# STM32L4R9xx register map
File version: 1.0
Registers are 32-bit, access not given, reset 0x0 unless marked. A register's access mark holds for its fields unless they carry their own. Offsets are from the block's base; [hi:lo] are bit positions; {n}, {i} and the like mark numbered series; 'fields as' and 'values as' point back to an identical list.

## OPAMP12_COMMON
Base 0x40007800
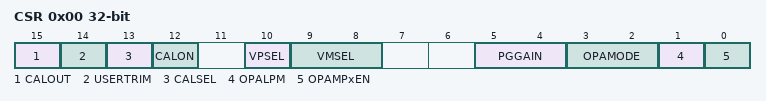
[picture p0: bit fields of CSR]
0x00 CSR
  [15] CALOUT, [14] USERTRIM, [13] CALSEL, [12] CALON, [10] VPSEL, [9:8] VMSEL, [5:4] PGGAIN, [3:2] OPAMODE, [1] OPALPM, [0] OPAMPxEN

## LPTIM1
Base 0x40007C00
Same registers: LPTIM2 0x40009400
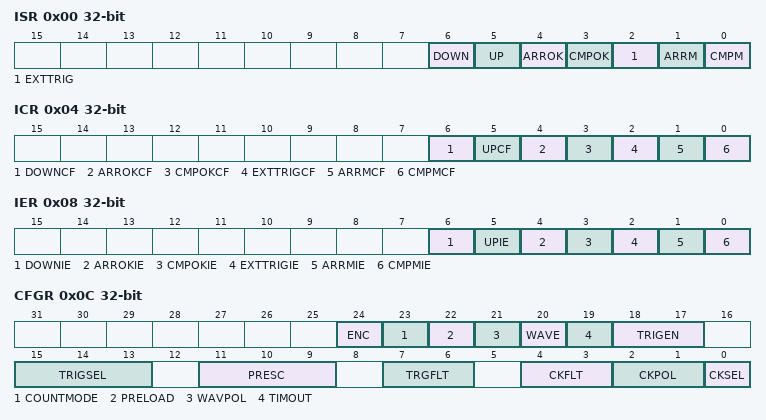
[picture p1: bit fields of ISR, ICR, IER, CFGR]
0x00 ISR
  [6] DOWN, [5] UP, [4] ARROK, [3] CMPOK, [2] EXTTRIG, [1] ARRM, [0] CMPM
0x04 ICR
  [6] DOWNCF, [5] UPCF, [4] ARROKCF, [3] CMPOKCF, [2] EXTTRIGCF, [1] ARRMCF, [0] CMPMCF
0x08 IER
  [6] DOWNIE, [5] UPIE, [4] ARROKIE, [3] CMPOKIE, [2] EXTTRIGIE, [1] ARRMIE, [0] CMPMIE
0x0C CFGR
  [24] ENC, [23] COUNTMODE, [22] PRELOAD, [21] WAVPOL, [20] WAVE, [19] TIMOUT, [18:17] TRIGEN, [15:13] TRIGSEL, [11:9] PRESC, [7:6] TRGFLT, [4:3] CKFLT, [2:1] CKPOL, [0] CKSEL
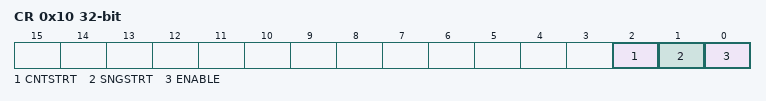
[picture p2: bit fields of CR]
0x10 CR
  [2] CNTSTRT, [1] SNGSTRT, [0] ENABLE
0x14 CMP
  [15:0] CMP
0x18 ARR
  [15:0] ARR
0x1C CNT
  [15:0] CNT
0x20 OR
  [1:0] OR

## SYSCFG
Base 0x40010000
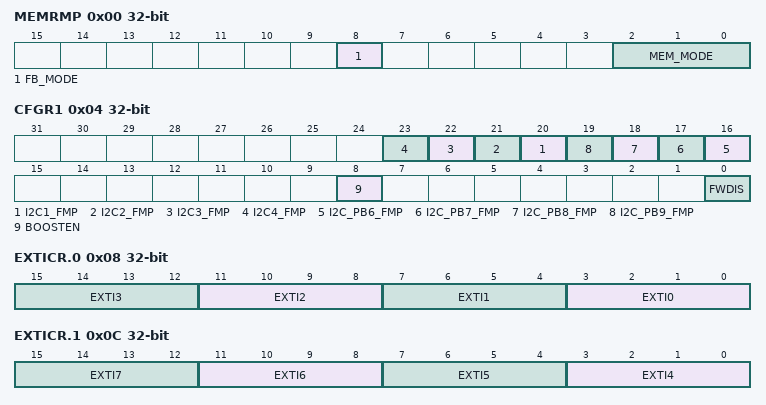
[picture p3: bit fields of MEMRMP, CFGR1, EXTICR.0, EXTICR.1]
0x00 MEMRMP
  [8] FB_MODE, [2:0] MEM_MODE
0x04 CFGR1
  [n+19] I2C{n}_FMP (n=1..4), [n+10] I2C_PB{n}_FMP (n=6..9), [8] BOOSTEN, [0] FWDIS
0x08 EXTICR.0
  [4n+3:4n] EXTI{n} (n=0..3)
0x0C EXTICR.1
  [4n-13:4n-16] EXTI{n} (n=4..7)
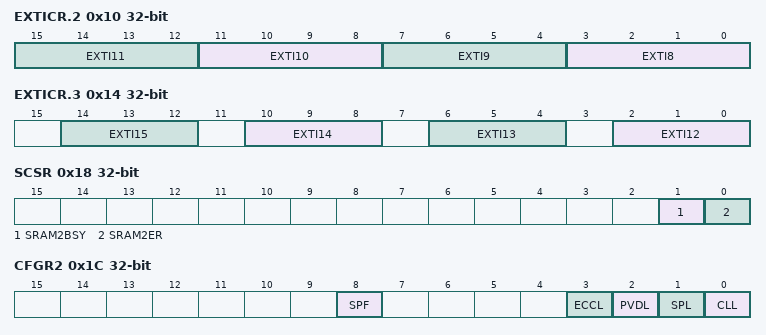
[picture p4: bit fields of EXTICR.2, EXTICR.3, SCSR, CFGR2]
0x10 EXTICR.2
  [4n-29:4n-32] EXTI{n} (n=8..11)
0x14 EXTICR.3
  [4n-46:4n-48] EXTI{n} (n=12..15)
0x18 SCSR
  [1] SRAM2BSY, [0] SRAM2ER
0x1C CFGR2
  [8] SPF, [3] ECCL, [2] PVDL, [1] SPL, [0] CLL
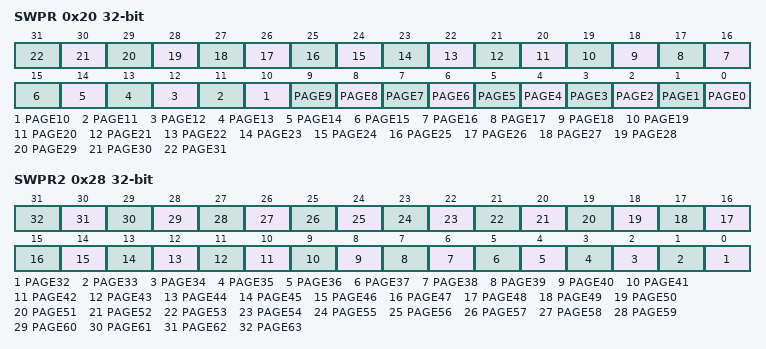
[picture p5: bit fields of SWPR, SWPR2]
0x20 SWPR
  [n] PAGE{n} (n=0..31)
0x24 SKR
  [7:0] KEY
0x28 SWPR2
  [n-32] PAGE{n} (n=32..63)

## VREFBUF
Base 0x40010030
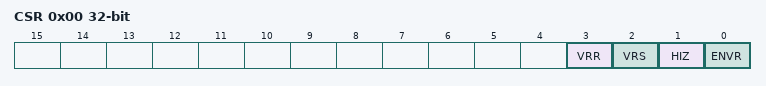
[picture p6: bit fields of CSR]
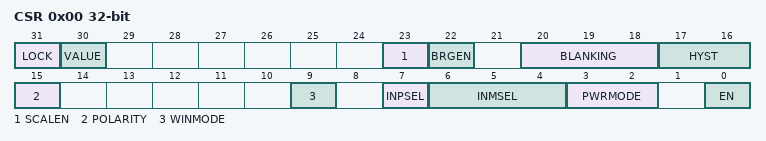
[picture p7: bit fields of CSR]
0x00 CSR
  [3] VRR, [2] VRS, [1] HIZ, [0] ENVR
0x04 CCR
  [5:0] TRIM

## COMP1
Base 0x40010200
Same registers: COMP2 0x40010204, COMP12_COMMON 0x40010204
0x00 CSR
  [31] LOCK, [30] VALUE, [23] SCALEN, [22] BRGEN, [20:18] BLANKING, [17:16] HYST, [15] POLARITY, [9] WINMODE, [7] INPSEL, [6:4] INMSEL, [3:2] PWRMODE, [0] EN

## EXTI
Base 0x40010400
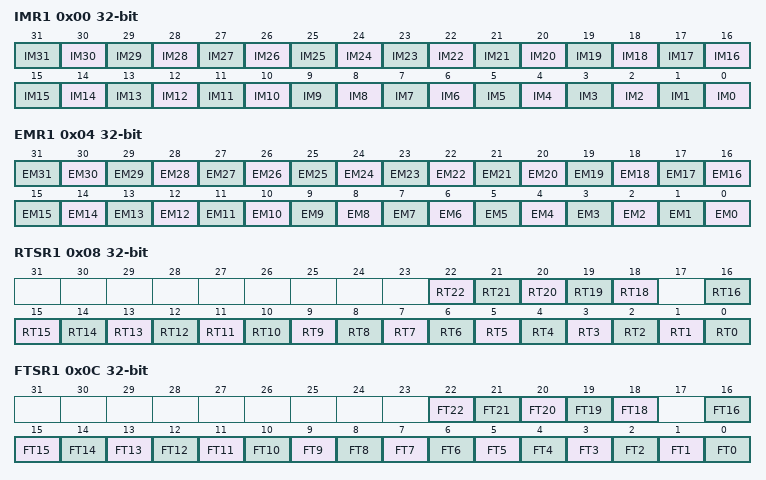
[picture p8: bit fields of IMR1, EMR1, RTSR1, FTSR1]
0x00 IMR1
  [n] IM{n} (n=0..31)
0x04 EMR1
  [n] EM{n} (n=0..31)
0x08 RTSR1
  [n] RT{n} (n=18..22), [n] RT{n} (n=0..16)
0x0C FTSR1
  [n] FT{n} (n=18..22), [n] FT{n} (n=0..16)
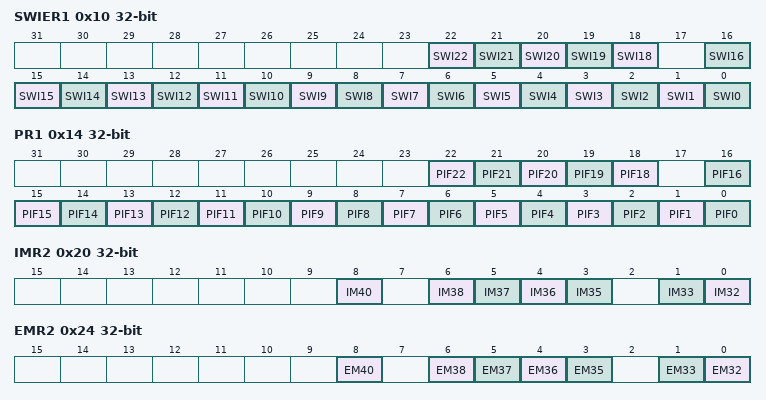
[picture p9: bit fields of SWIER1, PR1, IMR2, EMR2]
0x10 SWIER1
  [n] SWI{n} (n=18..22), [n] SWI{n} (n=0..16)
0x14 PR1
  [n] PIF{n} (n=18..22), [n] PIF{n} (n=0..16)
0x20 IMR2
  [8] IM40, [n-32] IM{n} (n=35..38), [1] IM33, [0] IM32
0x24 EMR2
  [8] EM40, [n-32] EM{n} (n=35..38), [1] EM33, [0] EM32
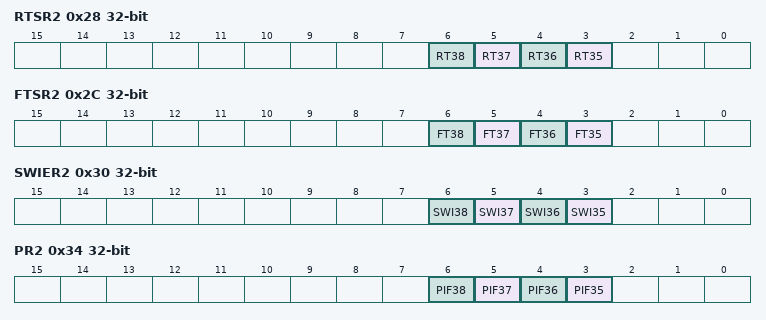
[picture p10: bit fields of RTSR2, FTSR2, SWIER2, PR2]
0x28 RTSR2
  [n-32] RT{n} (n=35..38)
0x2C FTSR2
  [n-32] FT{n} (n=35..38)
0x30 SWIER2
  [n-32] SWI{n} (n=35..38)
0x34 PR2
  [n-32] PIF{n} (n=35..38)

## FIREWALL
Base 0x40011C00
0x00 CSSA
0x04 CSL
0x08 NVDSSA
0x0C NVDSL
0x10 VDSSA
0x14 VDSL
0x20 CR

## SAI1
Base 0x40015400
Same registers: SAI2 0x40015800
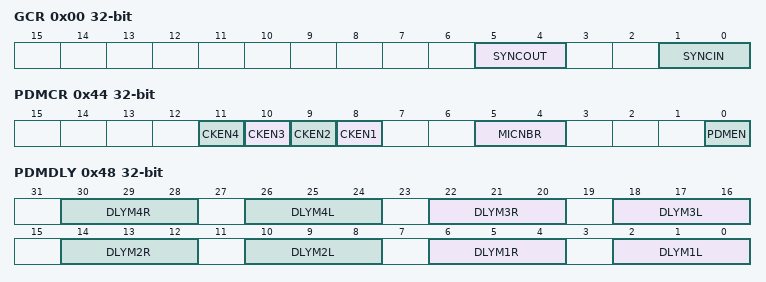
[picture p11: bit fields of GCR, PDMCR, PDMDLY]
0x00 GCR
  [5:4] SYNCOUT, [1:0] SYNCIN
0x04 CR1A
0x08 CR2A
0x10 FRCRA
0x1C SLOTRA
0x24 CR1B
0x28 CR2B
0x2C IMRA
0x30 FRCRB
0x3C SLOTRB
0x40 SRA
0x44 PDMCR
  [n+7] CKEN{n} (n=1..4), [5:4] MICNBR, [0] PDMEN
0x48 PDMDLY
  [8n-2:8n-4] DLYM{n}R (n=1..4), [8n-6:8n-8] DLYM{n}L (n=1..4)
0x4C IMRB
0x58 CLRFRA
0x60 SRB
0x74 DRA
0x78 CLRFRB
0x94 DRB

## DFSDM1
Base 0x40016000
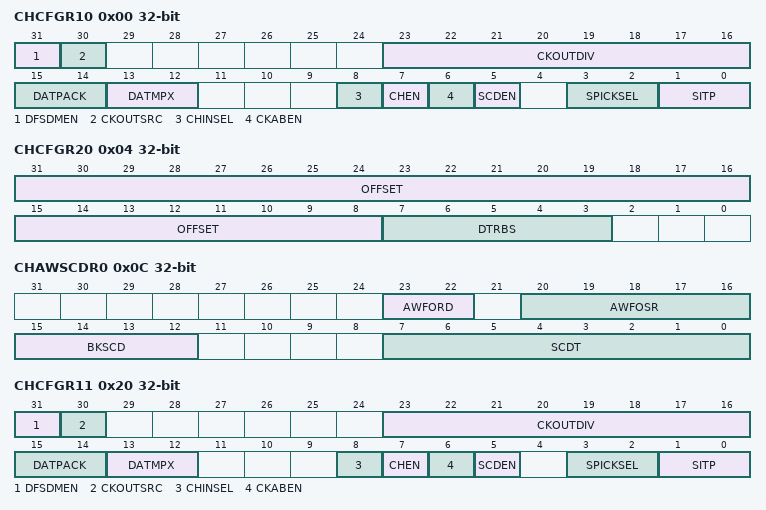
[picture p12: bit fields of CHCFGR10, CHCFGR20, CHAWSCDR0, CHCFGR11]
0x00 CHCFGR10
  [31] DFSDMEN, [30] CKOUTSRC, [23:16] CKOUTDIV, [15:14] DATPACK, [13:12] DATMPX, [8] CHINSEL, [7] CHEN, [6] CKABEN, [5] SCDEN, [3:2] SPICKSEL, [1:0] SITP
0x04 CHCFGR20
  [31:8] OFFSET, [7:3] DTRBS
0x0C CHAWSCDR0
  [23:22] AWFORD, [20:16] AWFOSR, [15:12] BKSCD, [7:0] SCDT
0x18 CHWDATAR0
0x20 CHCFGR11
  fields as CHCFGR10
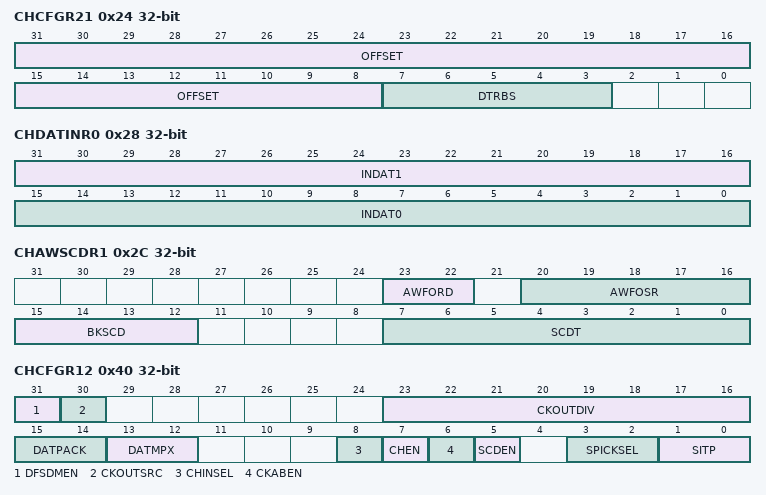
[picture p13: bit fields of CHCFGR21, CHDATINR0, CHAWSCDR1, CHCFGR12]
0x24 CHCFGR21
  [31:8] OFFSET, [7:3] DTRBS
0x28 CHDATINR0
  [31:16] INDAT1, [15:0] INDAT0
0x2C CHAWSCDR1
  [23:22] AWFORD, [20:16] AWFOSR, [15:12] BKSCD, [7:0] SCDT
0x38 CHWDATAR1
0x3C CHDLYR0
  [5:0] PLSSKP
0x40 CHCFGR12
  fields as CHCFGR10
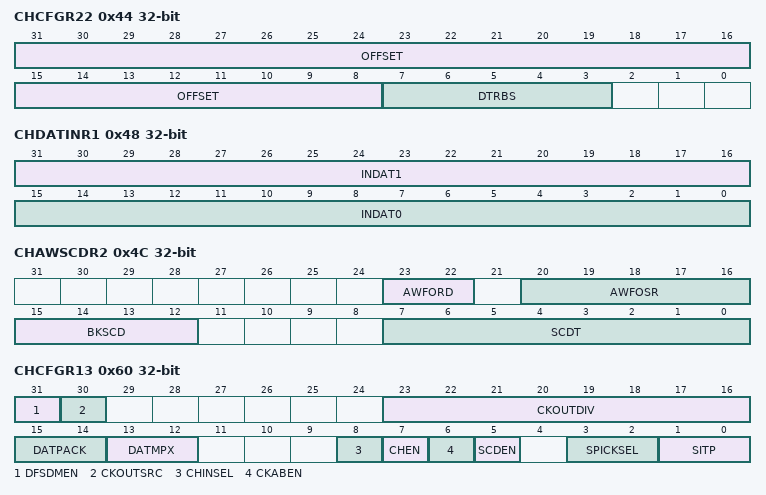
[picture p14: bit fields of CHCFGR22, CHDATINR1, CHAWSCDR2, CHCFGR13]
0x44 CHCFGR22
  [31:8] OFFSET, [7:3] DTRBS
0x48 CHDATINR1
  [31:16] INDAT1, [15:0] INDAT0
0x4C CHAWSCDR2
  [23:22] AWFORD, [20:16] AWFOSR, [15:12] BKSCD, [7:0] SCDT
0x58 CHWDATAR2
0x5C CHDLYR1
  [5:0] PLSSKP
0x60 CHCFGR13
  fields as CHCFGR10
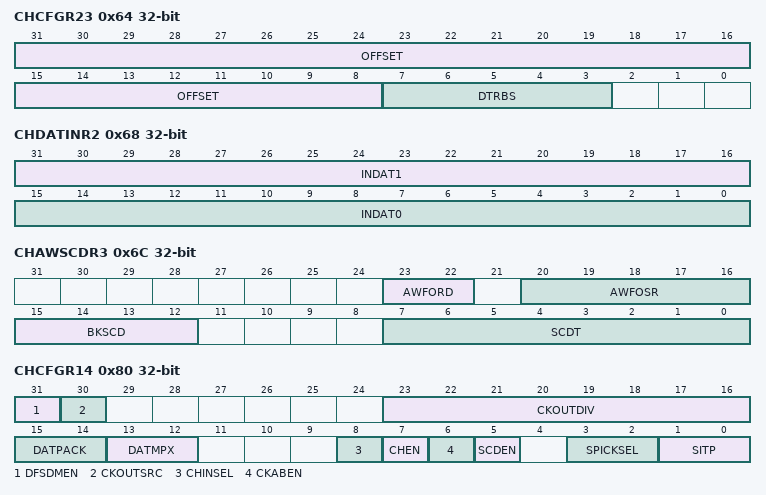
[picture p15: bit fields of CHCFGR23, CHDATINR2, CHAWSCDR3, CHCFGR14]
0x64 CHCFGR23
  [31:8] OFFSET, [7:3] DTRBS
0x68 CHDATINR2
  [31:16] INDAT1, [15:0] INDAT0
0x6C CHAWSCDR3
  [23:22] AWFORD, [20:16] AWFOSR, [15:12] BKSCD, [7:0] SCDT
0x78 CHWDATAR3
0x7C CHDLYR2
  [5:0] PLSSKP
0x80 CHCFGR14
  fields as CHCFGR10
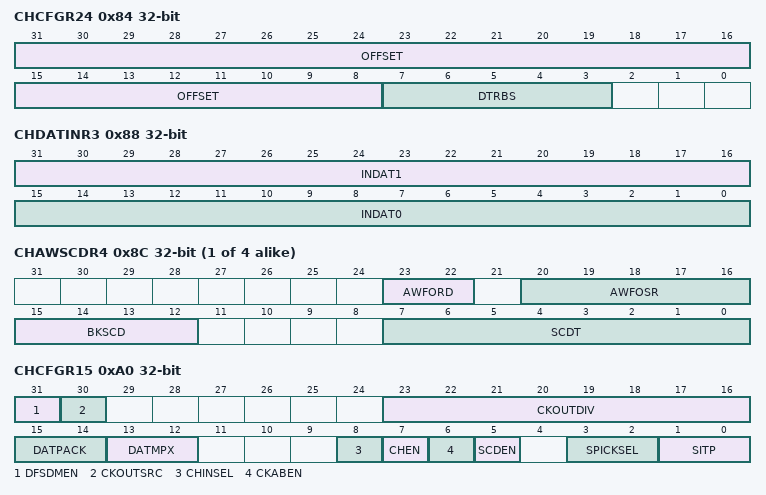
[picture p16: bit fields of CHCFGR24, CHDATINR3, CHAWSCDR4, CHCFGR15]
0x84 CHCFGR24
  [31:8] OFFSET, [7:3] DTRBS
0x88 CHDATINR3
  [31:16] INDAT1, [15:0] INDAT0
{0xC+0x20*i} CHAWSCDR{i} (i=4..7)
  [23:22] AWFORD, [20:16] AWFOSR, [15:12] BKSCD, [7:0] SCDT
{0x18+0x20*i} CHWDATAR{i} (i=4..7)
0x9C CHDLYR3
  [5:0] PLSSKP
0xA0 CHCFGR15
  fields as CHCFGR10
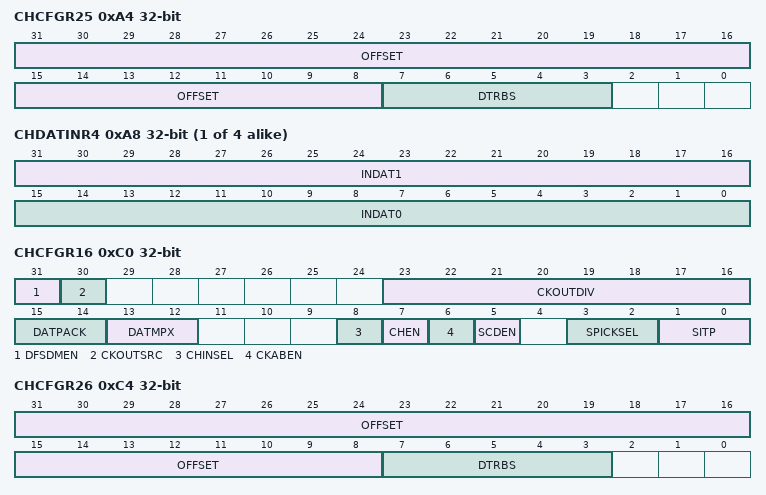
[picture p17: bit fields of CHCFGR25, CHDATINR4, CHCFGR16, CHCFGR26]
0xA4 CHCFGR25
  [31:8] OFFSET, [7:3] DTRBS
{0x28+0x20*i} CHDATINR{i} (i=4..7)
  [31:16] INDAT1, [15:0] INDAT0
{0x3C+0x20*i} CHDLYR{i} (i=4..7)
  [5:0] PLSSKP
0xC0 CHCFGR16
  fields as CHCFGR10
0xC4 CHCFGR26
  [31:8] OFFSET, [7:3] DTRBS
0xE0 CHCFGR17
  fields as CHCFGR10
0xE4 CHCFGR27
  [31:8] OFFSET, [7:3] DTRBS
0x100 CHCFGR10
  fields as CHCFGR10
0x104 CHCFGR20
  [31:8] OFFSET, [7:3] DTRBS
0x10C CHAWSCDR0
  [23:22] AWFORD, [20:16] AWFOSR, [15:12] BKSCD, [7:0] SCDT
0x118 CHWDATAR0
0x128 CHDATINR0
  [31:16] INDAT1, [15:0] INDAT0
0x13C CHDLYR0
  [5:0] PLSSKP
0x180 CHCFGR11
  fields as CHCFGR10
0x184 CHCFGR21
  [31:8] OFFSET, [7:3] DTRBS
0x18C CHAWSCDR1
  [23:22] AWFORD, [20:16] AWFOSR, [15:12] BKSCD, [7:0] SCDT
0x198 CHWDATAR1
0x1A8 CHDATINR1
  [31:16] INDAT1, [15:0] INDAT0
0x1BC CHDLYR1
  [5:0] PLSSKP
0x200 CHCFGR12
  fields as CHCFGR10
0x204 CHCFGR22
  [31:8] OFFSET, [7:3] DTRBS
0x20C CHAWSCDR2
  [23:22] AWFORD, [20:16] AWFOSR, [15:12] BKSCD, [7:0] SCDT
0x218 CHWDATAR2
0x228 CHDATINR2
  [31:16] INDAT1, [15:0] INDAT0
0x23C CHDLYR2
  [5:0] PLSSKP
0x280 CHCFGR13
  fields as CHCFGR10
0x284 CHCFGR23
  [31:8] OFFSET, [7:3] DTRBS
0x28C CHAWSCDR3
  [23:22] AWFORD, [20:16] AWFOSR, [15:12] BKSCD, [7:0] SCDT
0x298 CHWDATAR3
0x2A8 CHDATINR3
  [31:16] INDAT1, [15:0] INDAT0
0x2BC CHDLYR3
  [5:0] PLSSKP
